# AT32F426xx_v2 register map
Vendor: Keil; Series: AT32F426; File version: 1.0
CPU: CM4 r0p1, little endian, no MPU, FPU, 4 interrupt priority bits
Registers are 32-bit, read-write, reset 0x0 unless marked. A register's access mark holds for its fields unless they carry their own. Offsets are from the block's base; [hi:lo] are bit positions; {n}, {i} and the like mark numbered series.

## CMP — Comparator
Base 0x4001001C
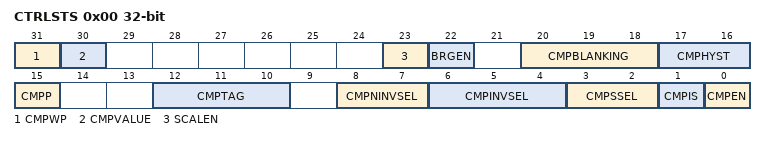
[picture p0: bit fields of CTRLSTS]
0x00 CTRLSTS — CMP control/status register
  [31] CMPWP — Comparator write protect
  [30] CMPVALUE ro — Comparator output value
  [23] SCALEN — Comparator scalen
  [22] BRGEN — Comparator brgen
  [20:18] CMPBLANKING — Comparator blanking
  [17:16] CMPHYST — Comparator hysteresis
  [15] CMPP — Comparator polarity
  [12:10] CMPTAG — Comparator output target
  [8:7] CMPNINVSEL — Comparator non-inverting input selection
  [6:4] CMPINVSEL — Comparator inverting selection
  [3:2] CMPSSEL — Comparator speed selection
  [1] CMPIS — Comparator input shift
  [0] CMPEN — Comparator enable bit
0x08 G_FILTER_EN
  [0] GFE — Glitch filter enable
0x0C HIGH_PULSE
  [5:0] H_PULSE_CNT — High pulse Count
0x10 LOW_PULSE
  [5:0] L_PULSE_CNT — Low pulse Count

## DEBUG — Debug support
Base 0xE0042000
0x00 IDCODE ro — DEBUG_IDCODE
  [31:0] PID
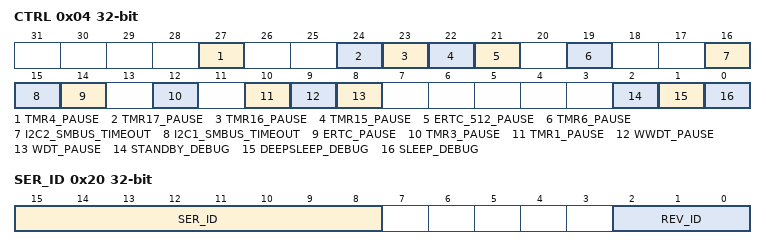
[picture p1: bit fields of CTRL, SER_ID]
0x04 CTRL — DEBUG_CTRL
  [27] TMR4_PAUSE, [24] TMR17_PAUSE, [23] TMR16_PAUSE, [22] TMR15_PAUSE, [21] ERTC_512_PAUSE, [19] TMR6_PAUSE, [16] I2C2_SMBUS_TIMEOUT, [15] I2C1_SMBUS_TIMEOUT, [14] ERTC_PAUSE, [12] TMR3_PAUSE, [10] TMR1_PAUSE, [9] WWDT_PAUSE, [8] WDT_PAUSE, [2] STANDBY_DEBUG, [1] DEEPSLEEP_DEBUG, [0] SLEEP_DEBUG
0x20 SER_ID ro — SERIES ID
  [15:8] SER_ID — series ID
  [2:0] REV_ID — version ID

## CRC — CRC calculation unit
Base 0x40023000
0x00 DT reset 0xFFFFFFFF — Data register
  [31:0] DT — Data Register
0x04 CDT — Common data register
  [7:0] CDT — Common Data
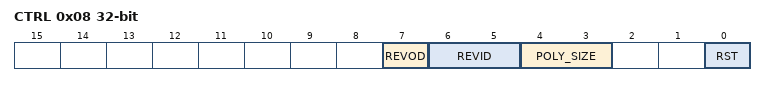
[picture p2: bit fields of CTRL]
0x08 CTRL — Control register
  [7] REVOD — Reverse output data
  [6:5] REVID — Reverse input data
  [4:3] POLY_SIZE — Polynomial size
  [0] RST — Reset CRC calculation unit
0x10 IDT reset 0xFFFFFFFF — Initial data register
  [31:0] IDT — Initial Data value
0x14 POLY reset 0x4C11DB7 — Polynomial coefficient register
  [31:0] POLY — polynomial coefficient

## FLASH — Flash memory controler
Base 0x40022000
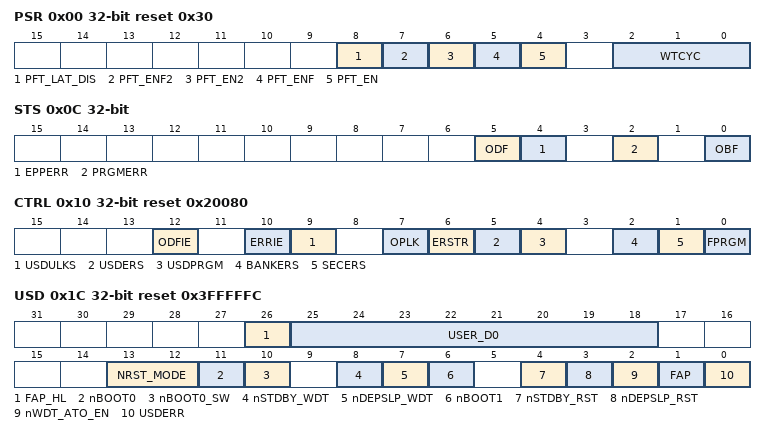
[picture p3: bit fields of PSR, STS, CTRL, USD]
0x00 PSR reset 0x30 — Performance selection register
  [8] PFT_LAT_DIS — Prefetch latency disable
  [7] PFT_ENF2 ro — Prefetch enabled flag 2
  [6] PFT_EN2 — Prefetch enable 2
  [5] PFT_ENF ro — Prefetch enabled flag
  [4] PFT_EN — Prefetch enable
  [2:0] WTCYC — Wait cycle
0x04 UNLOCK wo
  [31:0] UKVAL — Unlock key value
0x08 USD_UNLOCK wo
  [31:0] USD_UKVAL — User system data Unlock key value
0x0C STS — Status register
  [5] ODF — Operate done flag
  [4] EPPERR — Erase/program protection error
  [2] PRGMERR — program error
  [0] OBF ro — Operate busy flag
0x10 CTRL reset 0x20080 — Control register
  [12] ODFIE — Operation done flag interrupt enable
  [10] ERRIE — Error interrupt enable
  [9] USDULKS — User system data unlock success
  [7] OPLK — Operation lock
  [6] ERSTR — Erasing start
  [5] USDERS — User system data erase
  [4] USDPRGM — User system data program
  [2] BANKERS — Bank erase
  [1] SECERS — Sector erase
  [0] FPRGM — Flash program
0x14 ADDR wo — Address register
  [31:0] FA — Flash Address
0x1C USD ro reset 0x3FFFFFC — User system data register
  [26] FAP_HL — FAP high level
  [25:18] USER_D0 — User data 1
  [13:12] NRST_MODE — nrst or gpio mode
  [11] nBOOT0 — boot0
  [10] nBOOT0_SW — boot0_sw
  [8] nSTDBY_WDT — Standby wdt stop count
  [7] nDEPSLP_WDT — Deepsleep wdt stop count
  [6] nBOOT1 — boot1
  [4] nSTDBY_RST — Standby reset
  [3] nDEPSLP_RST — Deepsleep reset
  [2] nWDT_ATO_EN — WDT auto enable
  [1] FAP — FLASH access protection
  [0] USDERR — User system data error
0x20 EPPS ro reset 0xFFFFFFFF — Erase/program protection status register
  [31:0] EPPS — Erase/program protection status
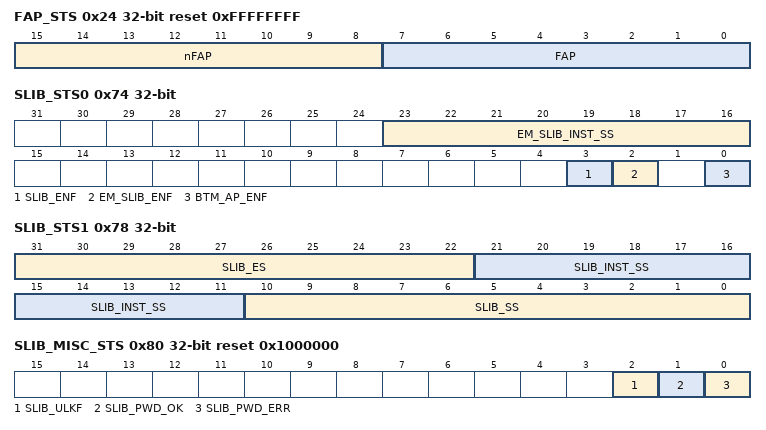
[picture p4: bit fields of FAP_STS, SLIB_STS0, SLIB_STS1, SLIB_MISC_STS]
0x24 FAP_STS ro reset 0xFFFFFFFF — FAP STATUS
  [15:8] nFAP — nFAP value
  [7:0] FAP — FAP value
0x74 SLIB_STS0 — sLib status 0 register
  [23:16] EM_SLIB_INST_SS — Extension memory sLib instruction start sector
  [3] SLIB_ENF — sLib enabled flag
  [2] EM_SLIB_ENF — Extension memory sLib enabled flag
  [0] BTM_AP_ENF — Boot memory store application code enabled flag
0x78 SLIB_STS1 — sLib status 1 register
  [31:22] SLIB_ES — sLib end sector
  [21:11] SLIB_INST_SS — sLib instruction start sector
  [10:0] SLIB_SS — sLib start sector
0x7C SLIB_PWD_CLR wo — SLIB password clear register
  [31:0] SLIB_PCLR_VAL — sLib password clear value
0x80 SLIB_MISC_STS reset 0x1000000 — sLib misc status register
  [2] SLIB_ULKF ro — sLib unlock flag
  [1] SLIB_PWD_OK ro — sLib password ok
  [0] SLIB_PWD_ERR ro — sLib password error
0x84 CRC_ADDR wo — Flash CRC data start address register
  [31:0] CRC_ADDR — CRC address
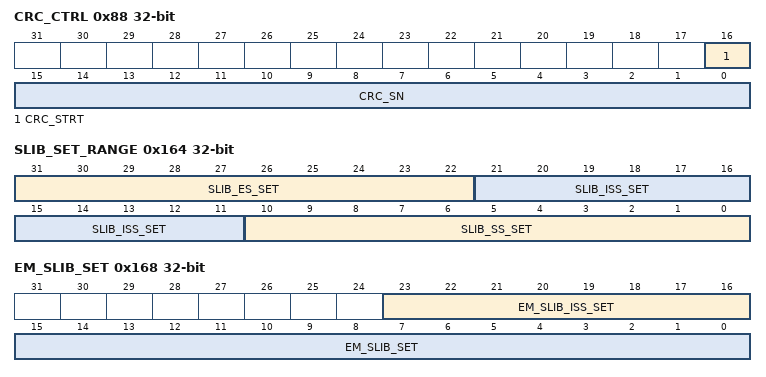
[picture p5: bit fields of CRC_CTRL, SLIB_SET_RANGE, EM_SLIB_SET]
0x88 CRC_CTRL — Flash CRC controll register
  [16] CRC_STRT wo — CRC start
  [15:0] CRC_SN — CRC sector numbler
0x8C CRC_CHKR ro — FLASH CRC check result register
  [31:0] FCRC_OUT — CRC32 verification result of flash user code or SLIB code
0x160 SLIB_SET_PWD wo — sLib password setting register
  [31:0] SLIB_PSET_VAL — sLib password setting val
0x164 SLIB_SET_RANGE wo — Configure sLib range register
  [31:22] SLIB_ES_SET — sLib end sector setting
  [21:11] SLIB_ISS_SET — sLib instruction start sector setting
  [10:0] SLIB_SS_SET — sLib start sector setting
0x168 EM_SLIB_SET wo — Extension momery slib set register
  [23:16] EM_SLIB_ISS_SET — Extension memory sLib instruction start sector setting
  [15:0] EM_SLIB_SET — Extension memory sLib setting
0x16C BTM_MODE_SET wo — Boot memory mode setting register
  [7:0] BTM_MODE_SET — Boot memory mode setting
0x170 SLIB_UNLOCK wo
  [31:0] SLIB_UKVAL — sLib unlock key value

## NVIC — Nested Vectored Interrupt Controller
Base 0xE000E000
0x04 ICTR ro — Interrupt Controller Type Register
  [3:0] INTLINESNUM — Total number of interrupt lines in groups
0x100 ISER0 — Interrupt Set-Enable Register
  [31:0] SETENA
0x104 ISER1 — Interrupt Set-Enable Register
  [31:0] SETENA
0x180 ICER0 — Interrupt Clear-Enable Register
  [31:0] CLRENA
0x184 ICER1 — Interrupt Clear-Enable Register
  [31:0] CLRENA
0x200 ISPR0 — Interrupt Set-Pending Register
  [31:0] SETPEND
0x204 ISPR1 — Interrupt Set-Pending Register
  [31:0] SETPEND
0x280 ICPR0 — Interrupt Clear-Pending Register
  [31:0] CLRPEND
0x284 ICPR1 — Interrupt Clear-Pending Register
  [31:0] CLRPEND
0x300 IABR0 ro — Interrupt Active Bit Register
  [31:0] ACTIVE
0x304 IABR1 ro — Interrupt Active Bit Register
  [31:0] ACTIVE
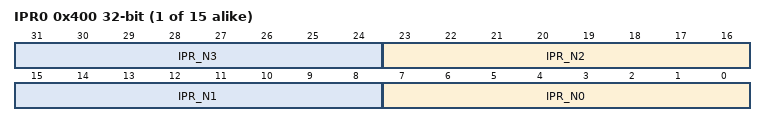
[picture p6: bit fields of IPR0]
{0x400+4i} IPR{i} (i=0..14) — Interrupt Priority Register
  [8n+7:8n] IPR_N{n} (n=0..3)
0xF00 STIR wo — Software Triggered Interrupt Register
  [8:0] INTID — interrupt to be triggered

## SCFG — System configuration controller
Base 0x40010000
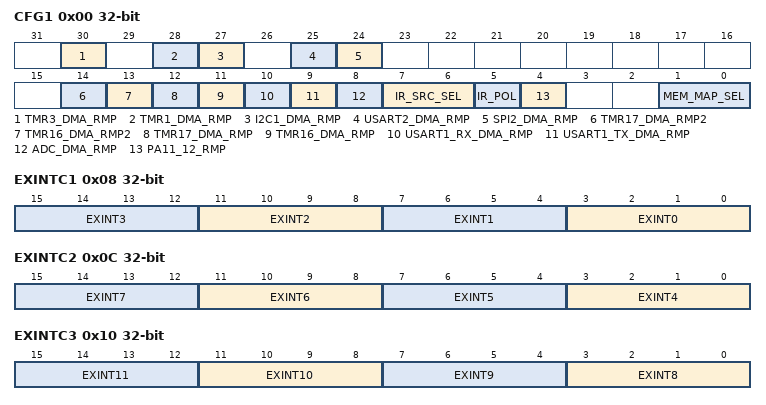
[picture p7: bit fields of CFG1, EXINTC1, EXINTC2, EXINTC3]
0x00 CFG1 — configuration register 1
  [30] TMR3_DMA_RMP — TMR3 DMA channel remap
  [28] TMR1_DMA_RMP — TMR1 DMA channel remap
  [27] I2C1_DMA_RMP — I2C1 DMA channel remap
  [25] USART2_DMA_RMP — USART2 DMA channel remap
  [24] SPI2_DMA_RMP — SPI DMA channel remap
  [14] TMR17_DMA_RMP2 — TMR17 DMA channel remap2
  [13] TMR16_DMA_RMP2 — TMR16 DMA channel remap2
  [12] TMR17_DMA_RMP — TMR17 DMA channel remap
  [11] TMR16_DMA_RMP — TMR16 DMA channel remap
  [10] USART1_RX_DMA_RMP — USART1 RX DMA channel remap
  [9] USART1_TX_DMA_RMP — USART1 TX DMA channel remap
  [8] ADC_DMA_RMP — ADC DMA channel remap
  [7:6] IR_SRC_SEL — IR signal source selection
  [5] IR_POL — IR output polarity selection
  [4] PA11_12_RMP — PA11_12 remap to PA9_10 enable
  [1:0] MEM_MAP_SEL — Memory address mapping selection bits
0x04 CFG2 — configuration register 2
  [24] CAN1_TST_SEL — CAN timestamp clock source selection
0x08 EXINTC1 — external interrupt configuration register 1
  [4n+3:4n] EXINT{n} (n=0..3) — EXINT {n} configuration bits
0x0C EXINTC2 — external interrupt configuration register 2
  [4n-13:4n-16] EXINT{n} (n=4..7) — EXINT {n} configuration bits
0x10 EXINTC3 — external interrupt configuration register 3
  [4n-29:4n-32] EXINT{n} (n=8..11) — EXINT {n} configuration bits
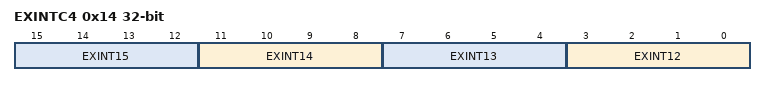
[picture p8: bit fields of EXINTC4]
0x14 EXINTC4 — external interrupt configuration register 4
  [4n-45:4n-48] EXINT{n} (n=12..15) — EXINT {n} configuration bits
0x60 IOCFG ro — IO config register
  [0] NRST_RMP — NRST pin remap status

## FPU — Floting point unit
Base 0xE000EF34
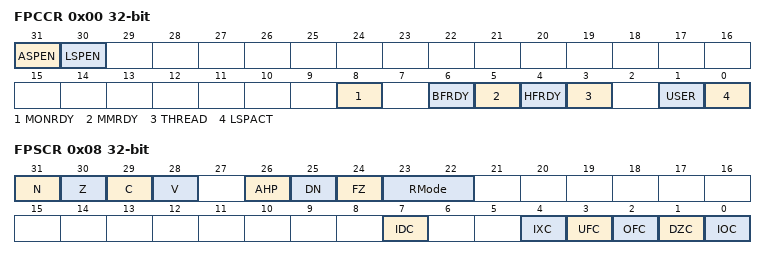
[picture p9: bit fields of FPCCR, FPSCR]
0x00 FPCCR — Floating-point context control register
  [31] ASPEN, [30] LSPEN, [8] MONRDY, [6] BFRDY, [5] MMRDY, [4] HFRDY, [3] THREAD, [1] USER, [0] LSPACT
0x04 FPCAR — Floating-point context address register
  [31:3] ADDRESS — Location of unpopulated floating-point
0x08 FPSCR — Floating-point status control register
  [31] N — Negative condition code flag
  [30] Z — Zero condition code flag
  [29] C — Carry condition code flag
  [28] V — Overflow condition code flag
  [26] AHP — Alternative half-precision control bit
  [25] DN — Default NaN mode control bit
  [24] FZ — Flush-to-zero mode control bit:
  [23:22] RMode — Rounding Mode control field
  [7] IDC — Input denormal cumulative exception bit.
  [4] IXC — Inexact cumulative exception bit
  [3] UFC — Underflow cumulative exception bit
  [2] OFC — Overflow cumulative exception bit
  [1] DZC — Division by zero cumulative exception bit.
  [0] IOC — Invalid operation cumulative exception bit
